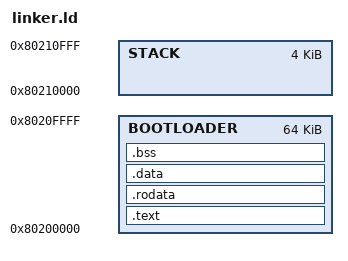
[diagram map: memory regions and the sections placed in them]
/* Crabby OS Bootloader 链接脚本 - 32位RISC-V学习版本 */
/* 这个文件告诉链接器如何组织我们的程序在内存中的布局 */

/* ========================================================================== */
/* 内存布局定义 - 基于QEMU virt机器的内存映射 */
/* ========================================================================== */

/* 
 * QEMU RISC-V virt机器的内存布局：
 * 0x00000000 - 0x00000FFF : 调试区域
 * 0x00001000 - 0x0000FFFF : BootROM (我们的bootloader将加载到这里)
 * 0x00010000 - 0x00017FFF : 平台级中断控制器 (PLIC)
 * 0x10000000 - 0x10000FFF : UART串口
 * 0x80000000 - 0x87FFFFFF : RAM (128MB)
 */

MEMORY {
    /* Bootloader区域 - 避开OpenSBI固件，从0x80200000开始 */
    /* OpenSBI固件通常占用0x80000000-0x80100000区域 */
    /* 我们给bootloader分配64KB的空间，这对于简单的bootloader足够了 */
    BOOTLOADER : ORIGIN = 0x80200000, LENGTH = 64K
    
    /* 栈区域 - 在bootloader之后 */
    /* 我们为栈分配4KB的空间 */
    STACK : ORIGIN = 0x80210000, LENGTH = 4K
}

/* ========================================================================== */
/* 程序入口点 */
/* ========================================================================== */

/* 告诉链接器程序的入口点是_start符号 */
ENTRY(_start)

/* ========================================================================== */
/* 段定义 - 定义程序的各个部分如何在内存中排列 */
/* ========================================================================== */

SECTIONS {
    /* 代码段 - 存放可执行指令 */
    .text : {
        /* 确保启动代码在最前面 */
        *(.text.start)      /* 我们的启动汇编代码 */
        *(.text .text.*)    /* 其他所有代码 */
    } > BOOTLOADER
    
    /* 只读数据段 - 存放常量 */
    .rodata : {
        *(.rodata .rodata.*)
    } > BOOTLOADER
    
    /* 已初始化数据段 - 存放有初值的全局变量 */
    .data : {
        *(.data .data.*)
    } > BOOTLOADER
    
    /* 未初始化数据段 - 存放没有初值的全局变量 */
    .bss : {
        /* 记录BSS段的开始和结束，用于清零 */
        __bss_start = .;
        *(.bss .bss.*)
        __bss_end = .;
    } > BOOTLOADER
    
    /* ====================================================================== */
    /* 栈定义 */
    /* ====================================================================== */
    
    /* 定义栈顶符号 - 汇编代码会使用这个符号 */
    /* 栈从高地址向低地址增长，所以栈顶是STACK区域的末尾 */
    __stack_top = ORIGIN(STACK) + LENGTH(STACK);
    
    /* 也定义栈底，虽然目前用不到 */
    __stack_bottom = ORIGIN(STACK);
    
    /* ====================================================================== */
    /* 丢弃不需要的段 */
    /* ====================================================================== */
    
    /* 丢弃调试信息和其他不需要的段，减小最终文件大小 */
    /DISCARD/ : {
        *(.comment)
        *(.gnu*)
        *(.note*)
        *(.eh_frame*)
    }
}

/* ========================================================================== */
/* 学习笔记 */
/* ========================================================================== */

/*
 * 这个链接脚本做了什么？
 * 
 * 1. 定义内存布局：
 *    - BOOTLOADER区域：存放我们的代码和数据
 *    - STACK区域：为程序栈预留空间
 * 
 * 2. 定义段的排列：
 *    - .text: 可执行代码
 *    - .rodata: 只读数据（常量）
 *    - .data: 已初始化的全局变量
 *    - .bss: 未初始化的全局变量
 * 
 * 3. 提供重要符号：
 *    - __stack_top: 栈顶地址，汇编代码用来设置栈指针
 *    - __bss_start, __bss_end: BSS段边界，用于清零未初始化变量
 * 
 * 为什么需要链接脚本？
 * - 告诉链接器如何组织程序的内存布局
 * - 确保代码加载到正确的内存地址
 * - 为栈和其他运行时需求预留空间
 * 
 * 下一步：
 * - 创建构建脚本来编译汇编代码
 * - 测试基础的bootloader是否能正确构建和运行
 */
